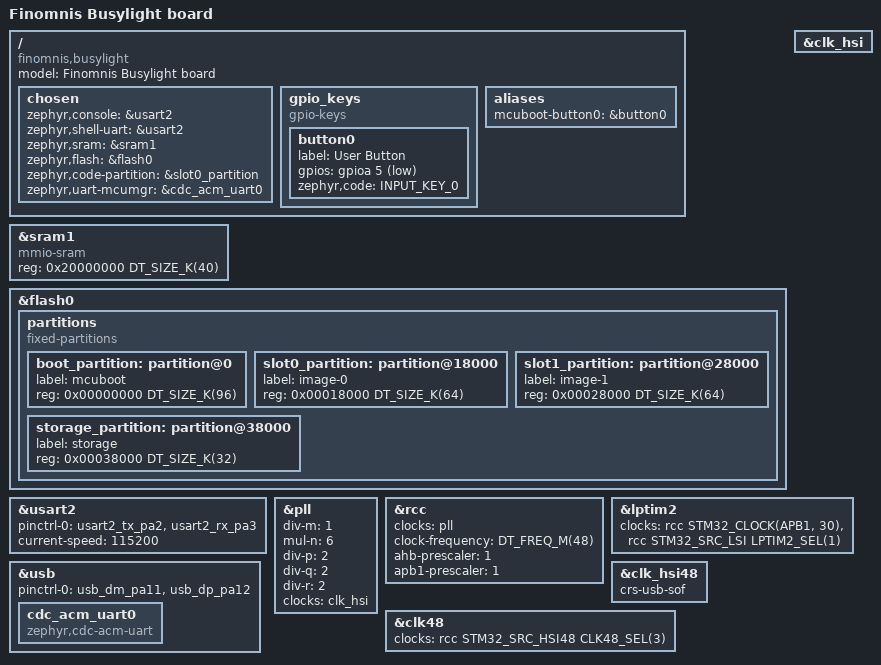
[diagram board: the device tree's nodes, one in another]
/dts-v1/;
#include <st/u0/stm32u073Xc.dtsi>
#include <st/u0/stm32u073ccux-pinctrl.dtsi>
#include <zephyr/dt-bindings/input/input-event-codes.h>
#include <zephyr/dt-bindings/input/stm32-tsc-defines.h>

/ {
    model = "Finomnis Busylight board";
    compatible = "finomnis,busylight";

    #address-cells = <1>;
    #size-cells = <1>;

    chosen {
        zephyr,console = &usart2;
        zephyr,shell-uart = &usart2;
        zephyr,sram = &sram1;
        zephyr,flash = &flash0;
        zephyr,code-partition = &slot0_partition;
        zephyr,uart-mcumgr = &cdc_acm_uart0;
    };

    gpio_keys {
        compatible = "gpio-keys";

        button0: button0 {
            label = "User Button";
            gpios = <&gpioa 5 (GPIO_PULL_UP | GPIO_ACTIVE_LOW)>;
            zephyr,code = <INPUT_KEY_0>;
        };
    };

    aliases {
        mcuboot-button0 = &button0;
    };
};

&sram1 {
    compatible = "mmio-sram";
    /delete-property/ zephyr,memory-region;
    reg = <0x20000000 DT_SIZE_K(40)>;
};
/delete-node/ &sram2;

&flash0 {
    partitions {
        compatible = "fixed-partitions";
        #address-cells = <1>;
        #size-cells = <1>;

        /*
         * Following flash partition is dedicated to the use of nucleo_u5a5zj_q
         * with TZEN=0 (so w/o TFM).
         */
        boot_partition: partition@0 {
            label = "mcuboot";
            reg = <0x00000000 DT_SIZE_K(96)>;
        };

        slot0_partition: partition@18000 {
            label = "image-0";
            reg = <0x00018000 DT_SIZE_K(64)>;
        };

        slot1_partition: partition@28000 {
            label = "image-1";
            reg = <0x00028000 DT_SIZE_K(64)>;
        };

        storage_partition: partition@38000 {
            label = "storage";
            reg = <0x00038000 DT_SIZE_K(32)>;
        };
    };
};

&usart2 {
    pinctrl-0 = <&usart2_tx_pa2 &usart2_rx_pa3>;
    pinctrl-names = "default";
    current-speed = <115200>;
    status = "okay";
};

&clk_hsi {
    status = "okay";
};

&pll {
    div-m = <1>;
    mul-n = <6>;
    div-p = <2>;
    div-q = <2>;
    div-r = <2>;
    clocks = <&clk_hsi>;
    status = "okay";
};

&rcc {
    clocks = <&pll>;
    clock-frequency = <DT_FREQ_M(48)>;
    ahb-prescaler = <1>;
    apb1-prescaler = <1>;
};

stm32_lp_tick_source: &lptim2 {
    clocks = <&rcc STM32_CLOCK(APB1, 30)>,
             <&rcc STM32_SRC_LSI LPTIM2_SEL(1)>;
    status = "okay";
};

zephyr_udc0: &usb {
    pinctrl-0 = <&usb_dm_pa11 &usb_dp_pa12>;
    pinctrl-names = "default";
    status = "okay";

    cdc_acm_uart0: cdc_acm_uart0 {
        compatible = "zephyr,cdc-acm-uart";
    };
};

&clk_hsi48 {
    crs-usb-sof;
    status = "okay";
};

&clk48 {
    clocks = <&rcc STM32_SRC_HSI48 CLK48_SEL(3)>;
    status = "okay";
};
